AUTOSAR XML (schema 00046)
standard types defined: uint16, uint8
package /VehicleProject
  system System
package /NM
  nm config NmConfig: can-nm-cluster-coupling=coupled-cluster=[DBCNetWork_CAN, DBCNetWork_INTER1_CAN]
    can nm cluster DBCNetWork_CAN: communication-cluster=DBCNetWork, nm-channel-id=0, nm-network-timeout=2, nm-user-data-length=6, nm-wait-bus-sleep-time=2
      4 x can nm node, all with nm-range-config={lower-can-id=1536, upper-can-id=1791}:
        TESTER: nm-if-ecu=TESTER_CAN, nm-node-id=0, rx-nm-pdu=Meg_NmTx_oDBCNetWork, tx-nm-pdu=Meg_NmRx_oDBCNetWork
        XB_SUP_D: nm-if-ecu=XB_SUP_D_CAN, nm-node-id=0, nm-passive-mode-enabled=true
        XB_SUP_E: nm-if-ecu=XB_SUP_E_CAN, nm-node-id=0, nm-passive-mode-enabled=true
        XB_SUP_F: controller=CT_DBCNetWork, nm-if-ecu=XB_SUP_F_CAN, nm-node-id=1, rx-nm-pdu=Meg_NmRx_oDBCNetWork, tx-nm-pdu=Meg_NmTx_oDBCNetWork
    can nm cluster DBCNetWork_INTER1_CAN: communication-cluster=DBCNetWork_INTER1, nm-channel-id=1, nm-network-timeout=2, nm-user-data-length=6, nm-wait-bus-sleep-time=2
      can nm node XB_SUP_F: controller=CT_DBCNetWork_INTER1, nm-if-ecu=XB_SUP_F_CAN, nm-node-id=1, nm-passive-mode-enabled=true, nm-range-config={lower-can-id=1536, upper-can-id=1791}
    nm-if-ecus:
      4 x nm ecu, all with nm-node-id-enabled=true, nm-user-data-enabled=true:
        TESTER_CAN
        XB_SUP_D_CAN: nm-passive-mode-enabled=true
        XB_SUP_E_CAN: nm-passive-mode-enabled=true
        XB_SUP_F_CAN: ecu-instance=XB_SUP_F, nm-passive-mode-enabled=true
package /TP
  can tp config DBCNetWork_CAN: communication-cluster=DBCNetWork, can-tp-ecu{cycle-time-main-function=0.005, ecu-instance=XB_SUP_F}
    can tp channel TPCH: channel-id=0, channel-mode=FULL-DUPLEX-MODE
    can-tp-connection addressing-format=STANDARD, can-tp-channel=TPCH, data-pdu=Meg_FunDiag_Tp_oDBCNetWork, receiver=TN_XB_SUP_F, ta-type=FUNCTIONAL, tp-sdu=Meg_FunDiag_oDBCNetWork, transmitter=TN_TESTER:
      ident Meg_FunDiag_oTN_TESTER
    can-tp-connection addressing-format=STANDARD, can-tp-channel=TPCH, data-pdu=Meg_PhyDiag_Tp_oDBCNetWork, flow-control-pdu=Meg_ResDiag_Tp_oDBCNetWork, receiver=TN_XB_SUP_F, ta-type=PHYSICAL, tp-sdu=Meg_PhyDiag_oDBCNetWork, transmitter=TN_TESTER:
      ident Meg_PhyDiag_oTN_XB_SUP_F
    can-tp-connection addressing-format=STANDARD, can-tp-channel=TPCH, data-pdu=Meg_ResDiag_Tp_oDBCNetWork, flow-control-pdu=Meg_PhyDiag_Tp_oDBCNetWork, receiver=TN_TESTER, ta-type=PHYSICAL, tp-sdu=Meg_ResDiag_oDBCNetWork, transmitter=TN_XB_SUP_F:
      ident Meg_ResDiag_oTN_XB_SUP_F
    can tp node TN_TESTER
    can tp node TN_XB_SUP_F: connector=CN_DBCNetWork
package /Cluster
  can cluster DBCNetWork: baudrate=500000, protocol-name=CAN  # Vector_XWXZ_CAN1
    can physical channel CHNL: comm-connectors=CN_DBCNetWork
      frame Meg_FunDiag_oDBCNetWork: id 0x7DF, to XB_SUP_F, frame-length=8, can-addressing-mode=STANDARD
        n pdu Meg_FunDiag_Tp_oDBCNetWork: length=8
      frame Meg_NmRx_oDBCNetWork: id 0x600, to XB_SUP_F, frame-length=8, can-addressing-mode=STANDARD
        nm pdu Meg_NmRx_oDBCNetWork: length=8, unused-bit-pattern=0
      frame Meg_NmTx_oDBCNetWork: id 0x601, from XB_SUP_F, frame-length=8, can-addressing-mode=STANDARD
        nm pdu Meg_NmTx_oDBCNetWork: length=8, unused-bit-pattern=0
      frame Meg_PhyDiag_oDBCNetWork: id 0x701, to XB_SUP_F, frame-length=8, can-addressing-mode=STANDARD
        n pdu Meg_PhyDiag_Tp_oDBCNetWork: length=8
      frame Meg_ResDiag_oDBCNetWork: id 0x751, from XB_SUP_F, frame-length=8, can-addressing-mode=STANDARD
        n pdu Meg_ResDiag_Tp_oDBCNetWork: length=8
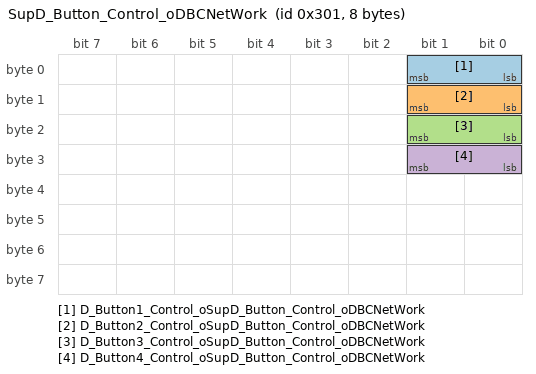
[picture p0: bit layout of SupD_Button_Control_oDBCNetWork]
      frame SupD_Button_Control_oDBCNetWork: id 0x301, to XB_SUP_F, frame-length=8, can-addressing-mode=STANDARD
        pdu SupD_Button_Control_oDBCNetWork: length=8, minimum-delay=0, transmission-mode-false-timing=cyclic-timing={time-offset=0, time-period=0.01}, transmission-mode-true-timing=cyclic-timing={time-offset=0, time-period=0.01}, unused-bit-pattern=0
          signal D_Button1_Control_oSupD_Button_Control_oDBCNetWork: start 1, 2 bit, big-endian, init-value=0, base-type=uint8, compu {0=Cx0_Button_Mode1, 1=Cx1_Button_Mode2, 2=Cx2_Button_Disable}, transfer-property=PENDING, to XB_SUP_F
          signal D_Button2_Control_oSupD_Button_Control_oDBCNetWork: start 9, 2 bit, big-endian, init-value=0, base-type=uint8, compu {0=Cx0_Button_Mode1, 1=Cx1_Button_Mode2, 2=Cx2_Button_Disable}, transfer-property=PENDING, to XB_SUP_F
          signal D_Button3_Control_oSupD_Button_Control_oDBCNetWork: start 17, 2 bit, big-endian, init-value=0, base-type=uint8, compu {0=Cx0_Button_Mode1, 1=Cx1_Button_Mode2, 2=Cx2_Button_Disable}, transfer-property=PENDING, to XB_SUP_F
          signal D_Button4_Control_oSupD_Button_Control_oDBCNetWork: start 25, 2 bit, big-endian, init-value=0, base-type=uint8, compu {0=Cx0_Button_Mode1, 1=Cx1_Button_Mode2, 2=Cx2_Button_Disable}, transfer-property=PENDING, to XB_SUP_F
          mapping SG_Sig_Grp_0x301: i-signal-group=SG_Sig_Grp_0x301_oSupD_Button_Control_oDBCNetWork, transfer-property=PENDING
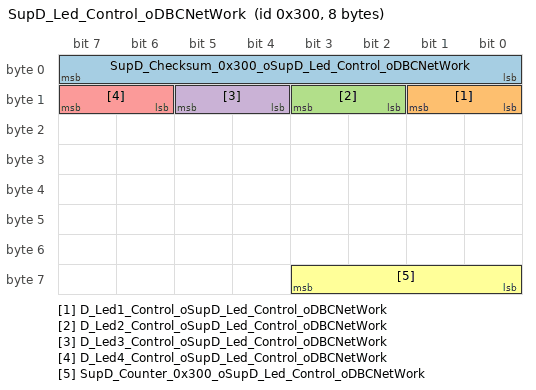
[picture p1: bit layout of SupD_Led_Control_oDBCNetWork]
      frame SupD_Led_Control_oDBCNetWork: id 0x300, to XB_SUP_F, frame-length=8, can-addressing-mode=STANDARD
        pdu SupD_Led_Control_oDBCNetWork: length=8, minimum-delay=0, transmission-mode-false-timing=cyclic-timing={time-offset=0, time-period=0.01}, transmission-mode-true-timing=cyclic-timing={time-offset=0, time-period=0.01}, unused-bit-pattern=0
          signal SupD_Checksum_0x300_oSupD_Led_Control_oDBCNetWork: start 7, 8 bit, big-endian, init-value=0, base-type=uint8, compu {identical}, range raw 0..255, transfer-property=PENDING, to XB_SUP_F
          signal D_Led1_Control_oSupD_Led_Control_oDBCNetWork: start 9, 2 bit, big-endian, init-value=2, base-type=uint8, compu {0=Cx0_Init, 1=Cx1_LED_ON, 2=Cx2_LED_OFF, 3=Cx3_Reserve}, transfer-property=PENDING, to XB_SUP_F
          signal D_Led2_Control_oSupD_Led_Control_oDBCNetWork: start 11, 2 bit, big-endian, init-value=2, base-type=uint8, compu {0=Cx0_Init, 1=Cx1_LED_ON, 2=Cx2_LED_OFF, 3=Cx3_Reserve}, transfer-property=PENDING, to XB_SUP_F
          signal D_Led3_Control_oSupD_Led_Control_oDBCNetWork: start 13, 2 bit, big-endian, init-value=2, base-type=uint8, compu {0=Cx0_Init, 1=Cx1_LED_ON, 2=Cx2_LED_OFF, 3=Cx3_Reserve}, transfer-property=PENDING, to XB_SUP_F
          signal D_Led4_Control_oSupD_Led_Control_oDBCNetWork: start 15, 2 bit, big-endian, init-value=2, base-type=uint8, compu {0=Cx0_Init, 1=Cx1_LED_ON, 2=Cx2_LED_OFF, 3=Cx3_Reserve}, transfer-property=PENDING, to XB_SUP_F
          signal SupD_Counter_0x300_oSupD_Led_Control_oDBCNetWork: start 59, 4 bit, big-endian, init-value=0, base-type=uint8, compu {identical}, range raw 0..14, transfer-property=PENDING, to XB_SUP_F
          mapping SG_Sig_Grp_0x300: i-signal-group=SG_Sig_Grp_0x300_oSupD_Led_Control_oDBCNetWork, transfer-property=PENDING
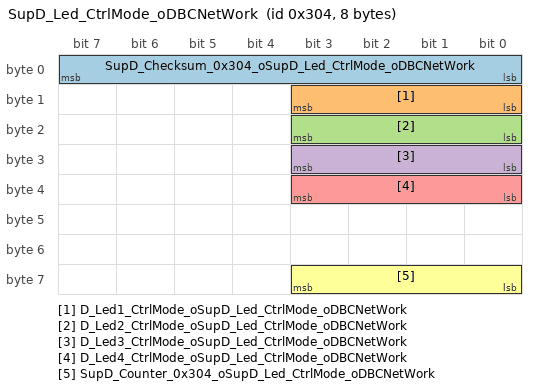
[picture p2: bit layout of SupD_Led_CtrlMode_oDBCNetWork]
      frame SupD_Led_CtrlMode_oDBCNetWork: id 0x304, to XB_SUP_F, frame-length=8, can-addressing-mode=STANDARD
        pdu SupD_Led_CtrlMode_oDBCNetWork: length=8, minimum-delay=0, transmission-mode-false-timing=cyclic-timing={time-offset=0, time-period=0.01}, transmission-mode-true-timing=cyclic-timing={time-offset=0, time-period=0.01}, unused-bit-pattern=0
          signal SupD_Checksum_0x304_oSupD_Led_CtrlMode_oDBCNetWork: start 7, 8 bit, big-endian, init-value=0, base-type=uint8, compu {identical}, range raw 0..255, transfer-property=PENDING, to XB_SUP_F
          signal D_Led1_CtrlMode_oSupD_Led_CtrlMode_oDBCNetWork: start 11, 4 bit, big-endian, init-value=0, base-type=uint8, compu {0=Cx0_Can_Control, 1=Cx1_Button_Control_Mode1, 2=Cx2_Button_Control_Mode2, 3=Cx3_Reserve} "Source signal range: [0,2]", transfer-property=PENDING, to XB_SUP_F
          signal D_Led2_CtrlMode_oSupD_Led_CtrlMode_oDBCNetWork: start 19, 4 bit, big-endian, init-value=0, base-type=uint8, compu {0=Cx0_Can_Control, 1=Cx1_Button_Control_Mode1, 2=Cx2_Button_Control_Mode2, 3=Cx3_Reserve} "Source signal range: [0,2]", transfer-property=PENDING, to XB_SUP_F
          signal D_Led3_CtrlMode_oSupD_Led_CtrlMode_oDBCNetWork: start 27, 4 bit, big-endian, init-value=0, base-type=uint8, compu {0=Cx0_Can_Control, 1=Cx1_Button_Control_Mode1, 2=Cx2_Button_Control_Mode2, 3=Cx3_Reserve} "Source signal range: [0,2]", transfer-property=PENDING, to XB_SUP_F
          signal D_Led4_CtrlMode_oSupD_Led_CtrlMode_oDBCNetWork: start 35, 4 bit, big-endian, init-value=0, base-type=uint8, compu {0=Cx0_Can_Control, 1=Cx1_Button_Control_Mode1, 2=Cx2_Button_Control_Mode2, 3=Cx3_Reserve} "Source signal range: [0,2]", transfer-property=PENDING, to XB_SUP_F
          signal SupD_Counter_0x304_oSupD_Led_CtrlMode_oDBCNetWork: start 59, 4 bit, big-endian, init-value=0, base-type=uint8, compu {identical}, range raw 0..14, transfer-property=PENDING, to XB_SUP_F
          mapping SG_Sig_Grp_0x304: i-signal-group=SG_Sig_Grp_0x304_oSupD_Led_CtrlMode_oDBCNetWork, transfer-property=PENDING
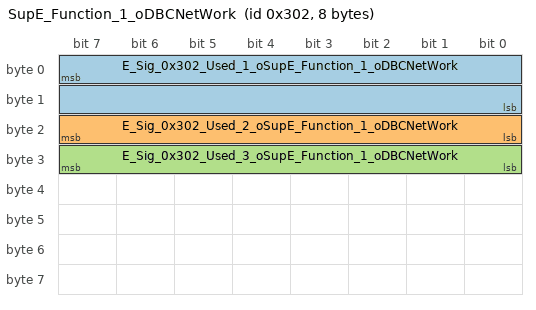
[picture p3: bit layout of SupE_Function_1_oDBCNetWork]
      frame SupE_Function_1_oDBCNetWork: id 0x302, to XB_SUP_F, frame-length=8, can-addressing-mode=STANDARD
        pdu SupE_Function_1_oDBCNetWork: length=8, minimum-delay=0, transmission-mode-false-timing=cyclic-timing={time-offset=0, time-period=0.01}, transmission-mode-true-timing=cyclic-timing={time-offset=0, time-period=0.01}, unused-bit-pattern=0
          signal E_Sig_0x302_Used_1_oSupE_Function_1_oDBCNetWork: start 7, 16 bit, big-endian, init-value=0, base-type=uint16, compu {identical}, range raw 0..65535, transfer-property=PENDING, to XB_SUP_F
          signal E_Sig_0x302_Used_2_oSupE_Function_1_oDBCNetWork: start 23, 8 bit, big-endian, init-value=0, base-type=uint8, compu {identical}, range raw 0..255, transfer-property=PENDING, to XB_SUP_F
          signal E_Sig_0x302_Used_3_oSupE_Function_1_oDBCNetWork: start 31, 8 bit, big-endian, init-value=0, base-type=uint8, compu {identical}, range raw 0..255, transfer-property=PENDING, to XB_SUP_F
          mapping SG_Sig_Grp_0x302: i-signal-group=SG_Sig_Grp_0x302_oSupE_Function_1_oDBCNetWork, transfer-property=PENDING
      frame SupF_Angle_oDBCNetWork: id 0x213, from XB_SUP_F, frame-length=8, can-addressing-mode=STANDARD
        pdu SupF_Angle_oDBCNetWork: length=8, minimum-delay=0, transmission-mode-false-timing=cyclic-timing={time-offset=0, time-period=0.01}, transmission-mode-true-timing=cyclic-timing={time-offset=0, time-period=0.01}, unused-bit-pattern=0
          signal F_AAA_Angle_oSupF_Angle_oDBCNetWork: start 7, 8 bit, big-endian, init-value=36, base-type=uint8, compu {phys=raw*0.5-10 for raw 0..40; unit o}, unit=o, transfer-property=PENDING
          mapping SG_Sig_Grp_0x213: i-signal-group=SG_Sig_Grp_0x213_oSupF_Angle_oDBCNetWork, transfer-property=PENDING
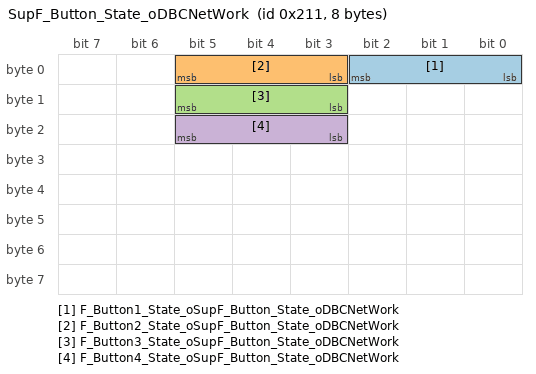
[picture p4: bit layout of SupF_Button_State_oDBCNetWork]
      frame SupF_Button_State_oDBCNetWork: id 0x211, from XB_SUP_F, frame-length=8, can-addressing-mode=STANDARD
        pdu SupF_Button_State_oDBCNetWork: length=8, minimum-delay=0, transmission-mode-false-timing=cyclic-timing={time-offset=0, time-period=0.05}, transmission-mode-true-timing=cyclic-timing={time-offset=0, time-period=0.05}, unused-bit-pattern=0
          signal F_Button1_State_oSupF_Button_State_oDBCNetWork: start 2, 3 bit, big-endian, init-value=0, base-type=uint8, compu {0=Cx0_Button_Push, 1=Cx1_Button_Release, 2=Cx2_Reserve}, range raw 0..7, transfer-property=PENDING
          signal F_Button2_State_oSupF_Button_State_oDBCNetWork: start 5, 3 bit, big-endian, init-value=0, base-type=uint8, compu {0=Cx0_Button_Push, 1=Cx1_Button_Release, 2=Cx2_Reserve}, range raw 0..7, transfer-property=PENDING
          signal F_Button3_State_oSupF_Button_State_oDBCNetWork: start 13, 3 bit, big-endian, init-value=0, base-type=uint8, compu {0=Cx0_Button_Push, 1=Cx1_Button_Release, 2=Cx2_Reserve}, range raw 0..7, transfer-property=PENDING
          signal F_Button4_State_oSupF_Button_State_oDBCNetWork: start 21, 3 bit, big-endian, init-value=0, base-type=uint8, compu {0=Cx0_Button_Push, 1=Cx1_Button_Release, 2=Cx2_Reserve}, range raw 0..7, transfer-property=PENDING
          mapping SG_Sig_Grp_0x211: i-signal-group=SG_Sig_Grp_0x211_oSupF_Button_State_oDBCNetWork, transfer-property=PENDING
      frame SupF_ComError_oDBCNetWork: id 0x216, from XB_SUP_F, frame-length=8, can-addressing-mode=STANDARD
        pdu SupF_ComError_oDBCNetWork: length=8, minimum-delay=0, transmission-mode-false-timing=cyclic-timing={time-offset=0, time-period=0.01}, transmission-mode-true-timing=cyclic-timing={time-offset=0, time-period=0.01}, unused-bit-pattern=0
          signal F_Mes_Lost_Error_oSupF_ComError_oDBCNetWork: start 7, 8 bit, big-endian, init-value=0, base-type=uint8, compu {0=Cx00_No_Message_Lost (No Message Lost), 1=Cx01_Message_0x300_Lost (Message 0x300 Lost), 2=Cx02_Message_0x301_Lost (Message 0x301 Lost), 3=Cx03_Message_0x302_Lost (Message 0x302 Lost), 4=Cx04_Message_0x303_Lost (Message 0x303 Lost), 5=Cx05_Message_0x304_Lost (Message 0x304 Lost)}, range raw 0..255, transfer-property=PENDING
          signal F_Meg_E2E_Error_oSupF_ComError_oDBCNetWork: start 15, 8 bit, big-endian, init-value=0, base-type=uint8, compu {0=Cx00_No_E2E_Error (No E2E Error), 1=Cx01_Message_0x301_E2E_Error (Message 0x301 E2E Error), 2=Cx02_Message_0x304_E2E_Error (Message 0x304 E2E Error)}, range raw 0..255, transfer-property=PENDING
          mapping SG_Sig_Grp_0x216: i-signal-group=SG_Sig_Grp_0x216_oSupF_ComError_oDBCNetWork, transfer-property=PENDING
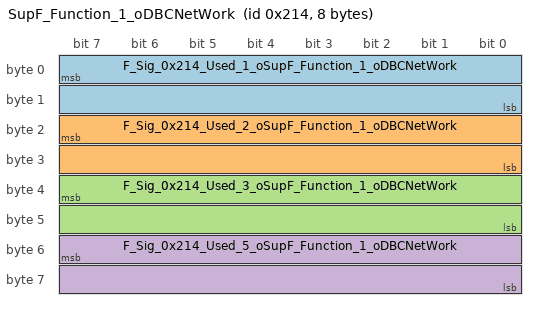
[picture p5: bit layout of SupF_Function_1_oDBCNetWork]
      frame SupF_Function_1_oDBCNetWork: id 0x214, from XB_SUP_F, frame-length=8, can-addressing-mode=STANDARD
        pdu SupF_Function_1_oDBCNetWork: length=8, minimum-delay=0, transmission-mode-false-timing=cyclic-timing={time-offset=0, time-period=0.02}, transmission-mode-true-timing=cyclic-timing={time-offset=0, time-period=0.02}, unused-bit-pattern=0
          signal F_Sig_0x214_Used_1_oSupF_Function_1_oDBCNetWork: start 7, 16 bit, big-endian, init-value=0, base-type=uint16, compu {identical}, range raw 0..65535, transfer-property=PENDING
          signal F_Sig_0x214_Used_2_oSupF_Function_1_oDBCNetWork: start 23, 16 bit, big-endian, init-value=0, base-type=uint16, compu {identical}, range raw 0..65535, transfer-property=PENDING
          signal F_Sig_0x214_Used_3_oSupF_Function_1_oDBCNetWork: start 39, 16 bit, big-endian, init-value=0, base-type=uint16, compu {identical}, range raw 0..65535, transfer-property=PENDING
          signal F_Sig_0x214_Used_5_oSupF_Function_1_oDBCNetWork: start 55, 16 bit, big-endian, init-value=0, base-type=uint16, compu {identical}, range raw 0..65535, transfer-property=PENDING
          mapping SG_Sig_Grp_0x214: i-signal-group=SG_Sig_Grp_0x214_oSupF_Function_1_oDBCNetWork, transfer-property=PENDING
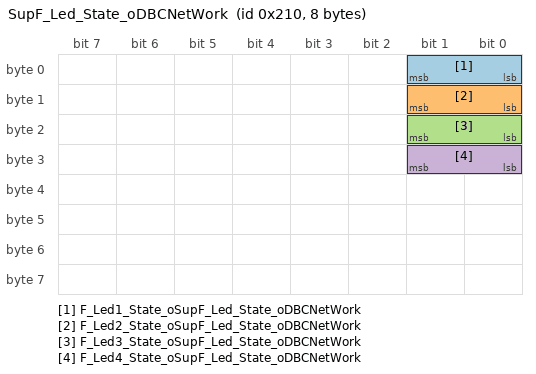
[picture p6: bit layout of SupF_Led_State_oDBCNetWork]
      frame SupF_Led_State_oDBCNetWork: id 0x210, from XB_SUP_F, frame-length=8, can-addressing-mode=STANDARD
        pdu SupF_Led_State_oDBCNetWork: length=8, minimum-delay=0, transmission-mode-false-timing=cyclic-timing={time-offset=0, time-period=0.1}, transmission-mode-true-timing=cyclic-timing={time-offset=0, time-period=0.1}, unused-bit-pattern=0
          signal F_Led1_State_oSupF_Led_State_oDBCNetWork: start 1, 2 bit, big-endian, init-value=0, base-type=uint8, compu {0=Cx0_LED_ON, 1=Cx1_LED_OFF, 2=Cx2_Reserve, 3=Cx3_Reserve}, transfer-property=PENDING
          signal F_Led2_State_oSupF_Led_State_oDBCNetWork: start 9, 2 bit, big-endian, init-value=0, base-type=uint8, compu {0=Cx0_LED_ON, 1=Cx1_LED_OFF, 2=Cx2_Reserve, 3=Cx3_Reserve}, transfer-property=PENDING
          signal F_Led3_State_oSupF_Led_State_oDBCNetWork: start 17, 2 bit, big-endian, init-value=0, base-type=uint8, compu {0=Cx0_LED_ON, 1=Cx1_LED_OFF, 2=Cx2_Reserve, 3=Cx3_Reserve}, transfer-property=PENDING
          signal F_Led4_State_oSupF_Led_State_oDBCNetWork: start 25, 2 bit, big-endian, init-value=0, base-type=uint8, compu {0=Cx0_LED_ON, 1=Cx1_LED_OFF, 2=Cx2_Reserve, 3=Cx3_Reserve}, transfer-property=PENDING
          mapping SG_Sig_Grp_0x210: i-signal-group=SG_Sig_Grp_0x210_oSupF_Led_State_oDBCNetWork, transfer-property=PENDING
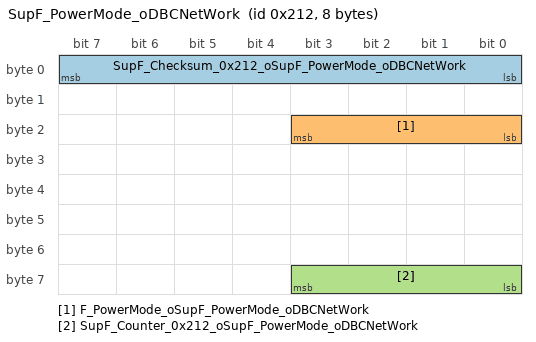
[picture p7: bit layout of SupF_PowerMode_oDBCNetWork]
      frame SupF_PowerMode_oDBCNetWork: id 0x212, from XB_SUP_F, frame-length=8, can-addressing-mode=STANDARD
        pdu SupF_PowerMode_oDBCNetWork: length=8, minimum-delay=0, transmission-mode-false-timing=cyclic-timing={time-offset=0, time-period=0.1}, transmission-mode-true-timing=cyclic-timing={time-offset=0, time-period=0.1}, unused-bit-pattern=0
          signal SupF_Checksum_0x212_oSupF_PowerMode_oDBCNetWork: start 7, 8 bit, big-endian, init-value=0, base-type=uint8, compu {identical}, range raw 0..255, transfer-property=PENDING
          signal F_PowerMode_oSupF_PowerMode_oDBCNetWork: start 19, 4 bit, big-endian, init-value=0, base-type=uint8, compu {0=Cx0_OFF, 1=Cx1_ON, 2=Cx2_Reserve}, range raw 0..7, transfer-property=PENDING
          signal SupF_Counter_0x212_oSupF_PowerMode_oDBCNetWork: start 59, 4 bit, big-endian, init-value=0, base-type=uint8, compu {identical}, range raw 0..14, transfer-property=PENDING
          mapping SG_Sig_Grp_0x212: i-signal-group=SG_Sig_Grp_0x212_oSupF_PowerMode_oDBCNetWork, transfer-property=PENDING
      pdu triggering PT_Meg_FunDiag: pdu=Meg_FunDiag_oDBCNetWork, to XB_SUP_F
      pdu triggering PT_Meg_PhyDiag: pdu=Meg_PhyDiag_oDBCNetWork, to XB_SUP_F
      pdu triggering PT_Meg_ResDiag: pdu=Meg_ResDiag_oDBCNetWork, from XB_SUP_F
  can cluster DBCNetWork_INTER1: baudrate=500000, protocol-name=CAN  # Vector_XWXZ_CAN0
    can physical channel CHNL: comm-connectors=CN_DBCNetWork_INTER1
      frame INTER_RECEIVE_oDBCNetWork_INTER1: id 0x200, to XB_SUP_F, frame-length=8, can-addressing-mode=STANDARD
        user defined pdu INTER_RECEIVE_oDBCNetWork_INTER1: length=8
      frame INTER_SEND_oDBCNetWork_INTER1: id 0x100, from XB_SUP_F, frame-length=8, can-addressing-mode=STANDARD
        user defined pdu INTER_SEND_oDBCNetWork_INTER1: length=8
package /ECU
  ecu instance XB_SUP_F: associated-com-i-pdu-group=[XB_SUP_F_oDBCNetWork_Rx, XB_SUP_F_oDBCNetWork_Tx]
    can communication controller CT_DBCNetWork: can-controller-attributes=can-controller-configuration-requirements={max-number-of-time-quanta-per-bit=20, max-sample-point=1, max-sync-jump-width=20, min-number-of-time-quanta-per-bit=10, min-sample-point=1, min-sync-jump-width=20}
    can communication controller CT_DBCNetWork_INTER1: can-controller-attributes=can-controller-configuration-requirements={max-number-of-time-quanta-per-bit=20, max-sample-point=1, max-sync-jump-width=20, min-number-of-time-quanta-per-bit=10, min-sample-point=1, min-sync-jump-width=20}
    can communication connector CN_DBCNetWork: comm-controller=CT_DBCNetWork
    can communication connector CN_DBCNetWork_INTER1: comm-controller=CT_DBCNetWork_INTER1
package /Gateway
  gateway XB_SUP_F: ecu=XB_SUP_F
package /IPDUGroup
  i signal i pdu group XB_SUP_F_oDBCNetWork_Rx: communication-direction=IN
    i-signal-i-pdus:
      SupD_Button_Control_oDBCNetWork
      SupD_Led_Control_oDBCNetWork
      SupD_Led_CtrlMode_oDBCNetWork
      SupE_Function_1_oDBCNetWork
  i signal i pdu group XB_SUP_F_oDBCNetWork_Tx: communication-direction=OUT
    i-signal-i-pdus:
      SupF_Angle_oDBCNetWork
      SupF_Button_State_oDBCNetWork
      SupF_ComError_oDBCNetWork
      SupF_Function_1_oDBCNetWork
      SupF_Led_State_oDBCNetWork
      SupF_PowerMode_oDBCNetWork
package /PDU
  dcm i pdu Meg_FunDiag_oDBCNetWork: length=7, diag-pdu-type=DIAG-REQUEST
  dcm i pdu Meg_PhyDiag_oDBCNetWork: length=8, diag-pdu-type=DIAG-REQUEST
  dcm i pdu Meg_ResDiag_oDBCNetWork: length=8, diag-pdu-type=DIAG-RESPONSE
package /ISignal
  10 x i signal group:
    SG_Sig_Grp_0x210_oSupF_Led_State_oDBCNetWork: i-signal=[F_Led1_State_oSupF_Led_State_oDBCNetWork, F_Led2_State_oSupF_Led_State_oDBCNetWork, F_Led3_State_oSupF_Led_State_oDBCNetWork, F_Led4_State_oSupF_Led_State_oDBCNetWork], system-signal-group=SG_Sig_Grp_0x210
    SG_Sig_Grp_0x211_oSupF_Button_State_oDBCNetWork: i-signal=[F_Button1_State_oSupF_Button_State_oDBCNetWork, F_Button2_State_oSupF_Button_State_oDBCNetWork, F_Button3_State_oSupF_Button_State_oDBCNetWork, F_Button4_State_oSupF_Button_State_oDBCNetWork], system-signal-group=SG_Sig_Grp_0x211
    SG_Sig_Grp_0x212_oSupF_PowerMode_oDBCNetWork: i-signal=[F_PowerMode_oSupF_PowerMode_oDBCNetWork, SupF_Checksum_0x212_oSupF_PowerMode_oDBCNetWork, SupF_Counter_0x212_oSupF_PowerMode_oDBCNetWork], system-signal-group=SG_Sig_Grp_0x212
    SG_Sig_Grp_0x213_oSupF_Angle_oDBCNetWork: i-signal=F_AAA_Angle_oSupF_Angle_oDBCNetWork, system-signal-group=SG_Sig_Grp_0x213
    SG_Sig_Grp_0x214_oSupF_Function_1_oDBCNetWork: i-signal=[F_Sig_0x214_Used_1_oSupF_Function_1_oDBCNetWork, F_Sig_0x214_Used_2_oSupF_Function_1_oDBCNetWork, F_Sig_0x214_Used_3_oSupF_Function_1_oDBCNetWork, F_Sig_0x214_Used_5_oSupF_Function_1_oDBCNetWork], system-signal-group=SG_Sig_Grp_0x214
    SG_Sig_Grp_0x216_oSupF_ComError_oDBCNetWork: i-signal=[F_Meg_E2E_Error_oSupF_ComError_oDBCNetWork, F_Mes_Lost_Error_oSupF_ComError_oDBCNetWork], system-signal-group=SG_Sig_Grp_0x216
    SG_Sig_Grp_0x300_oSupD_Led_Control_oDBCNetWork: i-signal=[D_Led1_Control_oSupD_Led_Control_oDBCNetWork, D_Led2_Control_oSupD_Led_Control_oDBCNetWork, D_Led3_Control_oSupD_Led_Control_oDBCNetWork, D_Led4_Control_oSupD_Led_Control_oDBCNetWork, SupD_Checksum_0x300_oSupD_Led_Control_oDBCNetWork, SupD_Counter_0x300_oSupD_Led_Control_oDBCNetWork], system-signal-group=SG_Sig_Grp_0x300
    SG_Sig_Grp_0x301_oSupD_Button_Control_oDBCNetWork: i-signal=[D_Button1_Control_oSupD_Button_Control_oDBCNetWork, D_Button2_Control_oSupD_Button_Control_oDBCNetWork, D_Button3_Control_oSupD_Button_Control_oDBCNetWork, D_Button4_Control_oSupD_Button_Control_oDBCNetWork], system-signal-group=SG_Sig_Grp_0x301
    SG_Sig_Grp_0x302_oSupE_Function_1_oDBCNetWork: i-signal=[E_Sig_0x302_Used_1_oSupE_Function_1_oDBCNetWork, E_Sig_0x302_Used_2_oSupE_Function_1_oDBCNetWork, E_Sig_0x302_Used_3_oSupE_Function_1_oDBCNetWork], system-signal-group=SG_Sig_Grp_0x302
    SG_Sig_Grp_0x304_oSupD_Led_CtrlMode_oDBCNetWork: i-signal=[D_Led1_CtrlMode_oSupD_Led_CtrlMode_oDBCNetWork, D_Led2_CtrlMode_oSupD_Led_CtrlMode_oDBCNetWork, D_Led3_CtrlMode_oSupD_Led_CtrlMode_oDBCNetWork, D_Led4_CtrlMode_oSupD_Led_CtrlMode_oDBCNetWork, SupD_Checksum_0x304_oSupD_Led_CtrlMode_oDBCNetWork, SupD_Counter_0x304_oSupD_Led_CtrlMode_oDBCNetWork], system-signal-group=SG_Sig_Grp_0x304
package /DataType/Unit
  unit U_o: display-name=o
